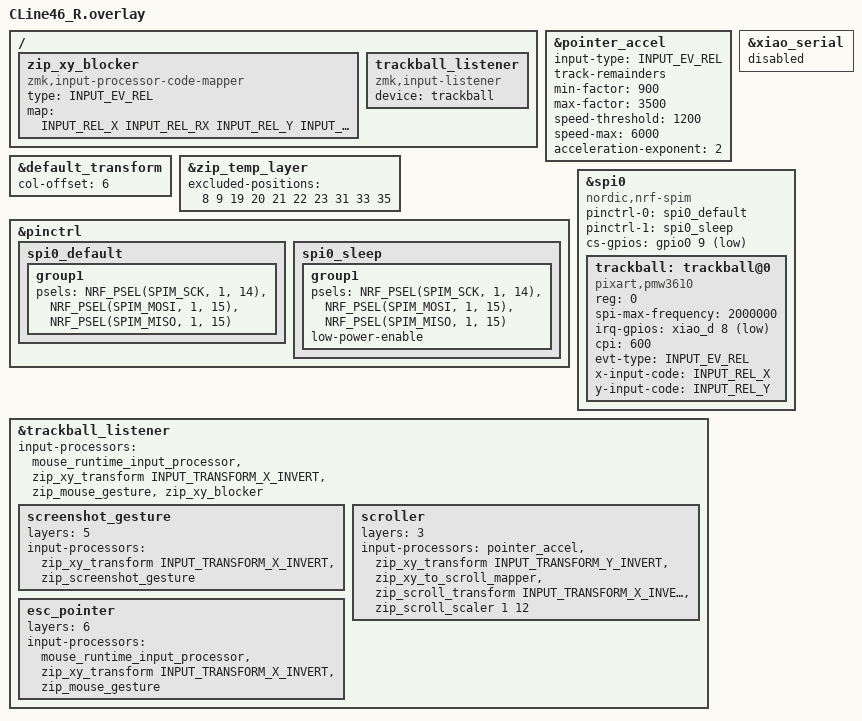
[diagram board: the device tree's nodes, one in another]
#include "CLine46.dtsi"
#include <zephyr/dt-bindings/input/input-event-codes.h>
#include <input/processors.dtsi>
#include <input/processors/runtime-input-processor.dtsi>
#include <behaviors/input_gestures_accel.dtsi>
#include <behaviors/battery_history_request.dtsi>

&pointer_accel {
    input-type = <INPUT_EV_REL>;
    track-remainders;
    min-factor = <900>;
    max-factor = <3500>;
    speed-threshold = <1200>;
    speed-max = <6000>;
    acceleration-exponent = <2>;
};

&default_transform {
    col-offset = <6>;
};


/ {
    zip_xy_blocker: zip_xy_blocker {
        compatible = "zmk,input-processor-code-mapper";
        #input-processor-cells = <0>;
        type = <INPUT_EV_REL>;
        map = <
            INPUT_REL_X INPUT_REL_RX
            INPUT_REL_Y INPUT_REL_RY
        >;
    };

    trackball_listener {
        status = "okay";
        compatible = "zmk,input-listener";
        device = <&trackball>;
    };
};

 &zip_temp_layer {
    excluded-positions = <8 9 19 20 21 22 23 31 33 35>;
};

&pinctrl {
    spi0_default: spi0_default {
        group1 {
            psels = <NRF_PSEL(SPIM_SCK, 1, 14)>,
                <NRF_PSEL(SPIM_MOSI, 1, 15)>,
                <NRF_PSEL(SPIM_MISO, 1, 15)>;
        };
    };

    spi0_sleep: spi0_sleep {
        group1 {
            psels = <NRF_PSEL(SPIM_SCK, 1, 14)>,
                <NRF_PSEL(SPIM_MOSI, 1, 15)>,
                <NRF_PSEL(SPIM_MISO, 1, 15)>;
            low-power-enable;
        };
    };
};


&xiao_serial { status = "disabled"; };

&spi0 {
    status = "okay";
    compatible = "nordic,nrf-spim";
    pinctrl-0 = <&spi0_default>;
    pinctrl-1 = <&spi0_sleep>;
    pinctrl-names = "default", "sleep";
    cs-gpios = <&gpio0 9 GPIO_ACTIVE_LOW>;  //P0.09を指定(CS)

    trackball: trackball@0 {
        status = "okay";
        compatible = "pixart,pmw3610";
        reg = <0>;
        spi-max-frequency = <2000000>;
        irq-gpios = <&xiao_d 8 (GPIO_ACTIVE_LOW | GPIO_PULL_UP)>;
        cpi = <600>;
        //swap-xy;
        evt-type = <INPUT_EV_REL>;
        x-input-code = <INPUT_REL_X>;
        y-input-code = <INPUT_REL_Y>;
    };
};

// Overrides for the input listener node
&trackball_listener {
    status = "okay";
    input-processors =
        <&mouse_runtime_input_processor>,
        //<&zip_xy_transform INPUT_TRANSFORM_Y_INVERT>;         //Y軸反転
        //<&zip_xy_transform INPUT_TRANSFORM_XY_SWAP>,        //X軸とY軸の入れ替え
        <&zip_xy_transform INPUT_TRANSFORM_X_INVERT>,       //X軸反転
        <&zip_mouse_gesture>,
        <&zip_xy_blocker>;                                  //通常時はカーソル移動を無効化

    screenshot_gesture {
        layers = <5>;
        input-processors =
            <&zip_xy_transform INPUT_TRANSFORM_X_INVERT>,
            <&zip_screenshot_gesture>;
    };

    scroller {
        layers = <3>;
        input-processors = 
            <&pointer_accel>,
            // <&zip_xy_transform INPUT_TRANSFORM_XY_SWAP>,        //X軸とY軸の入れ替え
            // <&zip_xy_transform INPUT_TRANSFORM_X_INVERT>,       //X軸反転
            <&zip_xy_transform INPUT_TRANSFORM_Y_INVERT>,       //Y軸反転
            <&zip_xy_to_scroll_mapper>,                         //スクロールモードに変更
            <&zip_scroll_transform INPUT_TRANSFORM_X_INVERT>,   //スクロールのX軸反転
            //<&zip_scroll_transform INPUT_TRANSFORM_Y_INVERT>,   //スクロールのY軸反転
            <&zip_scroll_scaler 1 12>;                           //スクロール量を1/12倍
    };

    esc_pointer {
        layers = <6>;
        input-processors =
            <&mouse_runtime_input_processor>,
            <&zip_xy_transform INPUT_TRANSFORM_X_INVERT>,
            <&zip_mouse_gesture>;
    };
};
